VERSION ""

NS_ :

BS_:

BU_: IMU PBX DDU7 VCU

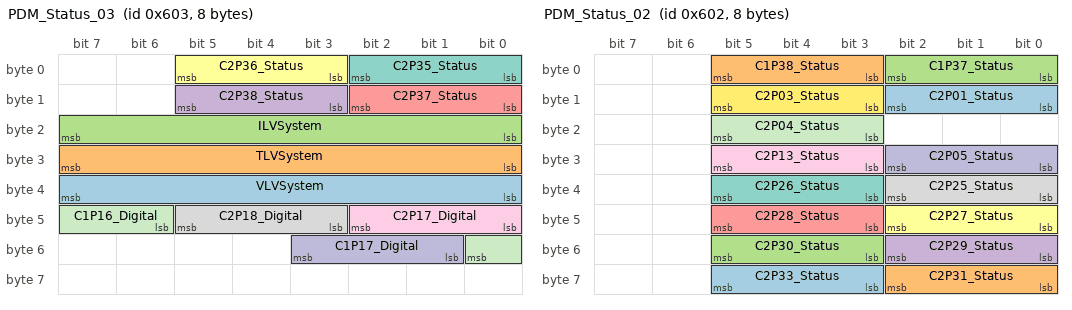
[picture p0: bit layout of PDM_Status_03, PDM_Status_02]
BO_ 1539 PDM_Status_03: 8 PBX
 SG_ VLVSystem : 32|8@1+ (0.1,0) [0|25.5] ""  VCU
 SG_ TLVSystem : 24|8@1+ (1,0) [0|255] ""  VCU
 SG_ ILVSystem : 16|8@1+ (1,0) [0|255] ""  VCU
 SG_ C2P38_Status : 11|3@1- (1,0) [0|0] ""  VCU
 SG_ C2P37_Status : 8|3@1- (1,0) [0|0] ""  VCU
 SG_ C2P36_Status : 3|3@1- (1,0) [0|0] ""  VCU
 SG_ C2P35_Status : 0|3@1- (1,0) [0|0] ""  VCU
 SG_ C2P18_Digital : 43|3@1- (1,0) [0|0] ""  VCU
 SG_ C2P17_Digital : 40|3@1- (1,0) [0|0] ""  VCU
 SG_ C1P17_Digital : 49|3@1- (1,0) [-4|3] ""  VCU
 SG_ C1P16_Digital : 46|3@1- (1,0) [0|0] ""  VCU

BO_ 1538 PDM_Status_02: 8 PBX
 SG_ C2P33_Status : 59|3@1- (1,0) [0|0] ""  VCU
 SG_ C2P31_Status : 56|3@1- (1,0) [0|0] ""  VCU
 SG_ C2P30_Status : 51|3@1- (1,0) [0|0] ""  VCU
 SG_ C2P29_Status : 48|3@1- (1,0) [0|0] ""  VCU
 SG_ C2P28_Status : 43|3@1- (1,0) [0|0] ""  VCU
 SG_ C2P27_Status : 40|3@1- (1,0) [0|0] ""  VCU
 SG_ C2P26_Status : 35|3@1- (1,0) [0|0] ""  VCU
 SG_ C2P25_Status : 32|3@1- (1,0) [0|0] ""  VCU
 SG_ C2P13_Status : 27|3@1- (1,0) [0|0] ""  VCU
 SG_ C2P05_Status : 24|3@1- (1,0) [0|0] ""  VCU
 SG_ C2P04_Status : 19|3@1- (1,0) [0|0] ""  VCU
 SG_ C2P03_Status : 11|3@1- (1,0) [0|0] ""  VCU
 SG_ C2P01_Status : 8|3@1- (1,0) [0|0] ""  VCU
 SG_ C1P38_Status : 3|3@1- (1,0) [0|0] ""  VCU
 SG_ C1P37_Status : 0|3@1- (1,0) [0|0] ""  VCU

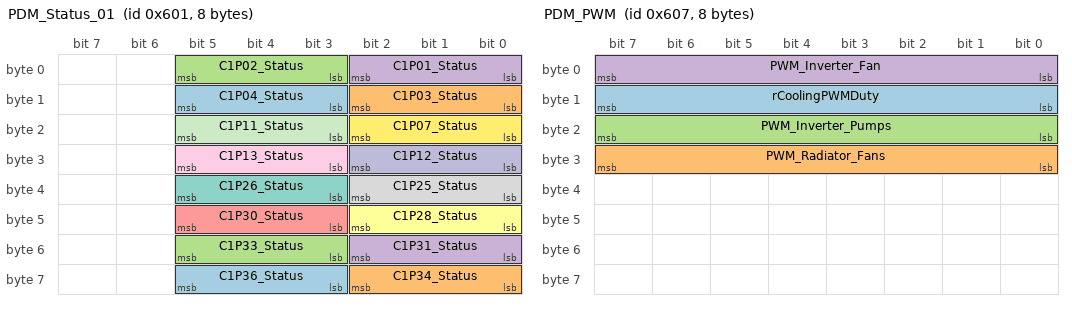
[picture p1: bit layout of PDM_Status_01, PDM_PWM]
BO_ 1537 PDM_Status_01: 8 PBX
 SG_ C1P36_Status : 59|3@1- (1,0) [0|0] ""  VCU
 SG_ C1P34_Status : 56|3@1- (1,0) [0|0] ""  VCU
 SG_ C1P33_Status : 51|3@1- (1,0) [0|0] ""  VCU
 SG_ C1P31_Status : 48|3@1- (1,0) [0|0] ""  VCU
 SG_ C1P30_Status : 43|3@1- (1,0) [0|0] ""  VCU
 SG_ C1P28_Status : 40|3@1- (1,0) [0|0] ""  VCU
 SG_ C1P26_Status : 35|3@1- (1,0) [0|0] ""  VCU
 SG_ C1P25_Status : 32|3@1- (1,0) [0|0] ""  VCU
 SG_ C1P13_Status : 27|3@1- (1,0) [0|0] ""  VCU
 SG_ C1P12_Status : 24|3@1- (1,0) [0|0] ""  VCU
 SG_ C1P11_Status : 19|3@1- (1,0) [0|0] ""  VCU
 SG_ C1P07_Status : 16|3@1- (1,0) [-4|3] ""  VCU
 SG_ C1P04_Status : 11|3@1- (1,0) [0|0] ""  VCU
 SG_ C1P03_Status : 8|3@1- (1,0) [0|0] ""  VCU
 SG_ C1P02_Status : 3|3@1- (1,0) [-4|3] ""  VCU
 SG_ C1P01_Status : 0|3@1- (1,0) [-4|3] ""  VCU

BO_ 1536 PDM_Req: 8 PBX
 SG_ C2P01 : 14|1@1+ (1,0) [0|0] ""  VCU
 SG_ C2P38 : 35|1@1+ (1,0) [0|0] ""  VCU
 SG_ C2P37 : 34|1@1+ (1,0) [0|0] ""  VCU
 SG_ C2P36 : 33|1@1+ (1,0) [0|1] ""  VCU
 SG_ C2P33 : 30|1@1+ (1,0) [0|1] ""  VCU
 SG_ C2P31 : 28|1@1+ (1,0) [0|1] ""  VCU
 SG_ C2P29 : 26|1@1+ (1,0) [0|1] ""  VCU
 SG_ C2P28 : 25|1@1+ (1,0) [0|0] ""  VCU
 SG_ C2P27 : 23|1@1+ (1,0) [0|0] ""  VCU
 SG_ C2P26 : 22|1@1+ (1,0) [0|0] ""  VCU
 SG_ C2P25 : 36|1@1+ (1,0) [0|1] ""  VCU
 SG_ C2P05 : 17|1@1+ (1,0) [0|0] ""  VCU
 SG_ C2P04 : 16|1@1+ (1,0) [0|1] ""  VCU
 SG_ C2P03 : 24|1@1+ (1,0) [0|0] ""  VCU
 SG_ C1P38 : 13|1@1+ (1,0) [0|0] ""  VCU
 SG_ C1P37 : 42|1@1+ (1,0) [0|1] ""  VCU
 SG_ C1P36 : 41|1@1+ (1,0) [0|1] ""  VCU
 SG_ C1P34 : 11|1@1+ (1,0) [0|1] ""  VCU
 SG_ C1P33 : 10|1@1+ (1,0) [0|1] ""  VCU
 SG_ C1P30 : 8|1@1+ (1,0) [0|1] ""  VCU
 SG_ C1P28 : 7|1@1+ (1,0) [0|1] ""  VCU
 SG_ C1P25 : 5|1@1+ (1,0) [0|1] ""  VCU
 SG_ C1P13 : 3|1@1+ (1,0) [0|1] ""  VCU
 SG_ C1P11_Hbridge : 39|2@1+ (1,0) [0|3] ""  VCU
 SG_ C1P07 : 38|1@1+ (1,0) [0|1] ""  VCU
 SG_ C1P04 : 2|1@1+ (1,0) [0|1] ""  VCU
 SG_ C1P03 : 1|1@1+ (1,0) [0|0] ""  VCU
 SG_ C1P02 : 0|1@1+ (1,0) [0|1] ""  VCU
 SG_ C1P01 : 37|1@1+ (1,0) [0|1] ""  VCU
 SG_ BReadyToDriveBuzzerRequest : 32|1@1+ (1,0) [0|1] ""  VCU
 SG_ BInvLVOnRequest : 9|1@1+ (1,0) [0|1] ""  VCU
 SG_ BBrakeLightOnRequest : 27|1@1+ (1,0) [0|1] ""  VCU
 SG_ BAccumulatorFanOnRequest : 15|1@1+ (1,0) [0|255] ""  VCU

BO_ 1543 PDM_PWM: 8 PBX
 SG_ rCoolingPWMDuty : 8|8@1+ (1,0) [0|255] ""  VCU
 SG_ PWM_Radiator_Fans : 24|8@1+ (1,0) [0|255] ""  VCU
 SG_ PWM_Inverter_Pumps : 16|8@1+ (1,0) [0|0] ""  VCU
 SG_ PWM_Inverter_Fan : 0|8@1+ (1,0) [0|0] ""  VCU

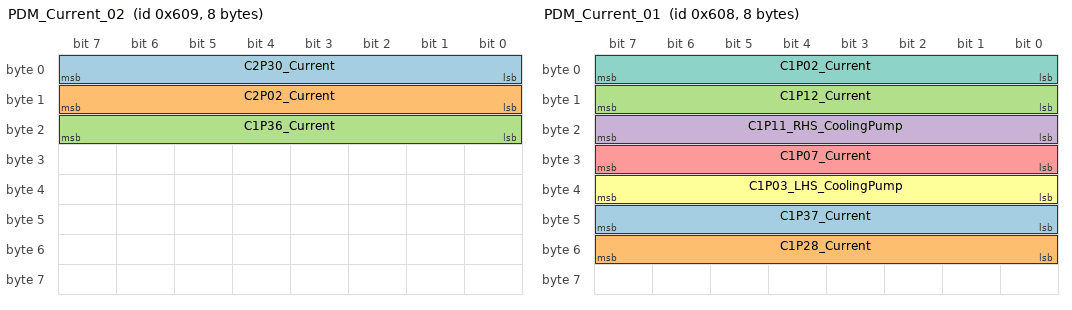
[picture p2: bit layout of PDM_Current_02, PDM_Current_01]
BO_ 1545 PDM_Current_02: 8 PBX
 SG_ C2P30_Current : 0|8@1- (1,0) [0|0] ""  VCU
 SG_ C2P02_Current : 8|8@1- (1,0) [-128|127] ""  VCU
 SG_ C1P36_Current : 16|8@1- (1,0) [0|0] ""  VCU

BO_ 1544 PDM_Current_01: 8 PBX
 SG_ C1P37_Current : 40|8@1- (1,0) [0|0] ""  VCU
 SG_ C1P28_Current : 48|8@1- (1,0) [-128|127] ""  VCU
 SG_ C1P12_Current : 8|8@1- (1,0) [-128|127] ""  VCU
 SG_ C1P11_RHS_CoolingPump : 16|8@1- (1,0) [0|0] ""  VCU
 SG_ C1P07_Current : 24|8@1- (1,0) [-128|127] ""  VCU
 SG_ C1P03_LHS_CoolingPump : 32|8@1- (1,0) [-128|127] ""  VCU
 SG_ C1P02_Current : 0|8@1- (1,0) [-128|127] ""  VCU

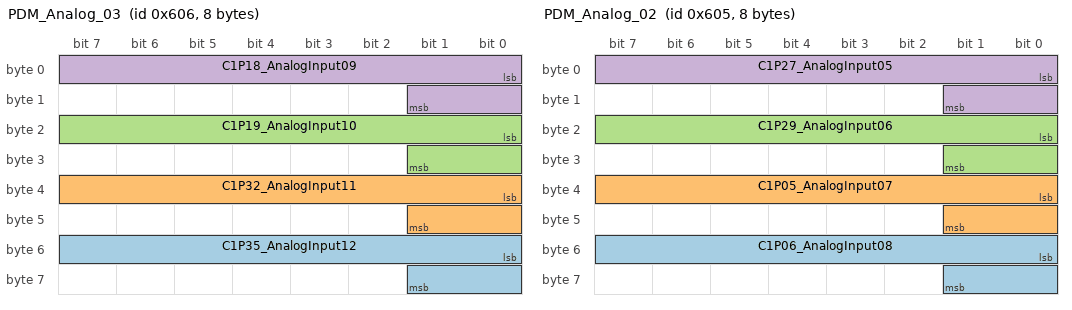
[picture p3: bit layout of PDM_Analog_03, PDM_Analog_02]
BO_ 1542 PDM_Analog_03: 8 PBX
 SG_ C1P35_AnalogInput12 : 48|10@1+ (0.005,0) [0|5.115] ""  VCU
 SG_ C1P32_AnalogInput11 : 32|10@1+ (0.005,0) [0|5.115] ""  VCU
 SG_ C1P19_AnalogInput10 : 16|10@1+ (0.005,0) [0|0] ""  VCU
 SG_ C1P18_AnalogInput09 : 0|10@1+ (0.005,0) [0|0] ""  VCU

BO_ 1541 PDM_Analog_02: 8 PBX
 SG_ C1P06_AnalogInput08 : 48|10@1+ (0.005,0) [0|5.115] ""  VCU
 SG_ C1P05_AnalogInput07 : 32|10@1+ (0.005,0) [0|5.115] ""  VCU
 SG_ C1P29_AnalogInput06 : 16|10@1+ (0.005,0) [0|5.115] ""  VCU
 SG_ C1P27_AnalogInput05 : 0|10@1+ (0.005,0) [0|5.115] ""  VCU

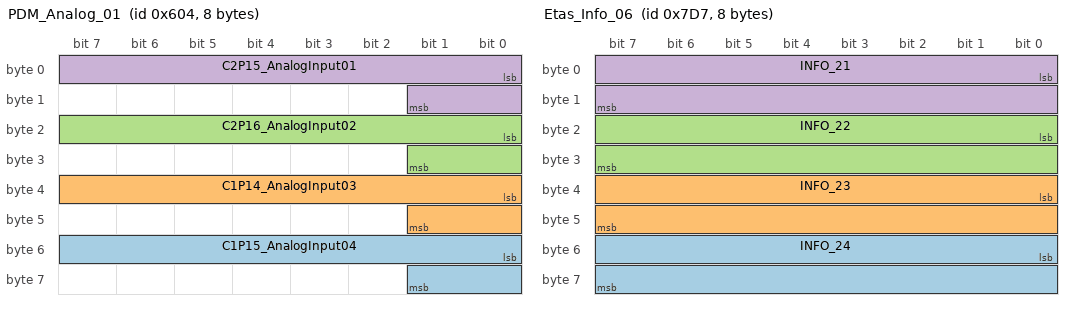
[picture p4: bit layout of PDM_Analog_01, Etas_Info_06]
BO_ 1540 PDM_Analog_01: 8 PBX
 SG_ C1P15_AnalogInput04 : 48|10@1+ (0.005,0) [0|5.115] ""  VCU
 SG_ C1P14_AnalogInput03 : 32|10@1+ (0.005,0) [0|5.115] ""  VCU
 SG_ C2P16_AnalogInput02 : 16|10@1+ (0.005,0) [0|5.115] ""  VCU
 SG_ C2P15_AnalogInput01 : 0|10@1+ (0.005,0) [0|5.115] ""  VCU

BO_ 2007 Etas_Info_06: 8 Vector__XXX
 SG_ INFO_24 : 48|16@1- (1,0) [0|0] "" Vector__XXX
 SG_ INFO_23 : 32|16@1- (1,0) [0|0] "" Vector__XXX
 SG_ INFO_22 : 16|16@1- (1,0) [0|0] "" Vector__XXX
 SG_ INFO_21 : 0|16@1- (1,0) [0|0] "" Vector__XXX

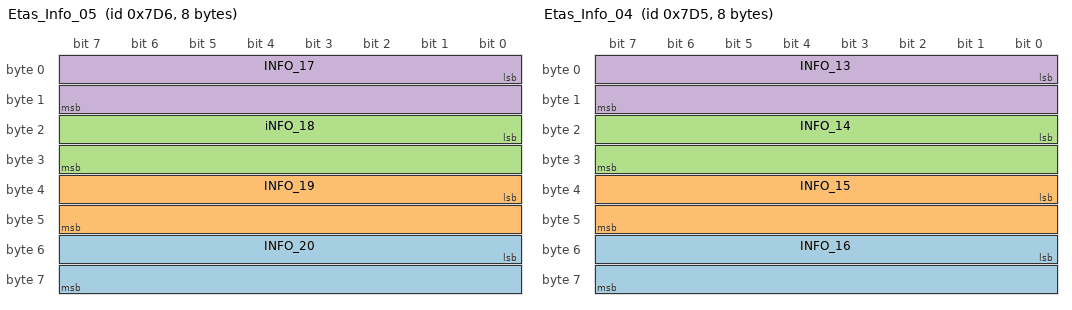
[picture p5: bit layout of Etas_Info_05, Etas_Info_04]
BO_ 2006 Etas_Info_05: 8 Vector__XXX
 SG_ INFO_20 : 48|16@1- (1,0) [0|0] "" Vector__XXX
 SG_ INFO_19 : 32|16@1- (1,0) [0|0] "" Vector__XXX
 SG_ iNFO_18 : 16|16@1- (1,0) [0|0] "" Vector__XXX
 SG_ INFO_17 : 0|16@1- (1,0) [0|0] "" Vector__XXX

BO_ 2005 Etas_Info_04: 8 Vector__XXX
 SG_ INFO_16 : 48|16@1- (1,0) [0|0] "" Vector__XXX
 SG_ INFO_15 : 32|16@1- (1,0) [0|0] "" Vector__XXX
 SG_ INFO_14 : 16|16@1- (1,0) [0|0] "" Vector__XXX
 SG_ INFO_13 : 0|16@1- (1,0) [0|0] "" Vector__XXX

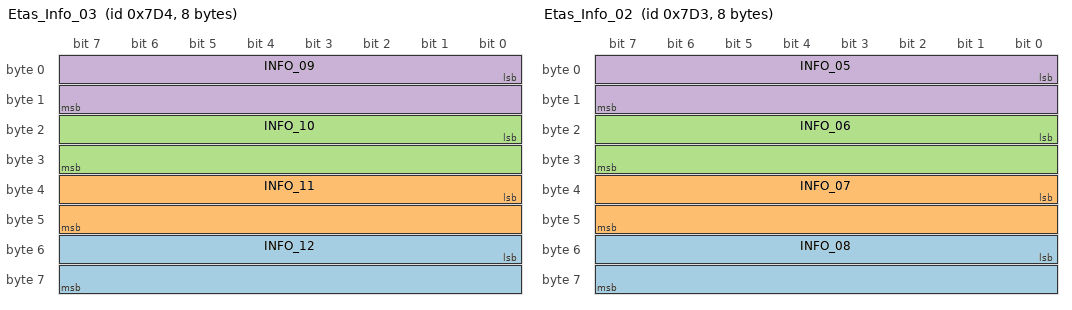
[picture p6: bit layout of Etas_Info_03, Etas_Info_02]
BO_ 2004 Etas_Info_03: 8 Vector__XXX
 SG_ INFO_12 : 48|16@1- (1,0) [0|0] "" Vector__XXX
 SG_ INFO_11 : 32|16@1- (1,0) [0|0] "" Vector__XXX
 SG_ INFO_10 : 16|16@1- (1,0) [0|0] "" Vector__XXX
 SG_ INFO_09 : 0|16@1- (1,0) [0|0] "" Vector__XXX

BO_ 2003 Etas_Info_02: 8 Vector__XXX
 SG_ INFO_08 : 48|16@1- (1,0) [0|0] "" Vector__XXX
 SG_ INFO_07 : 32|16@1- (1,0) [0|0] "" Vector__XXX
 SG_ INFO_06 : 16|16@1- (1,0) [0|0] "" Vector__XXX
 SG_ INFO_05 : 0|16@1- (1,0) [0|0] "" Vector__XXX

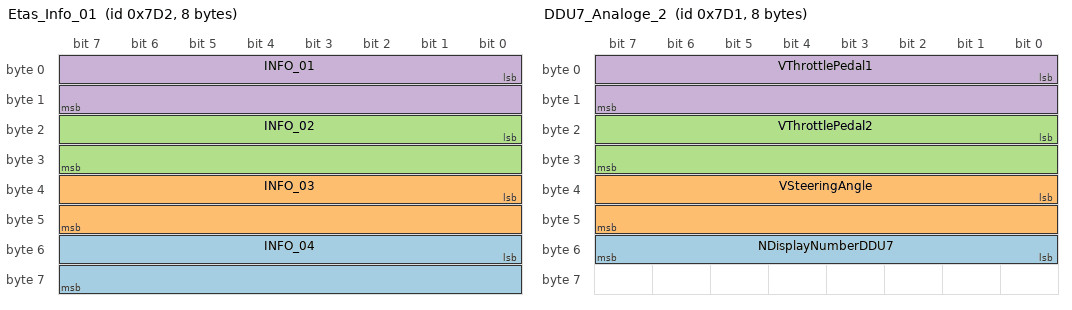
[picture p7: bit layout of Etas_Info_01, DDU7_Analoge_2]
BO_ 2002 Etas_Info_01: 8 Vector__XXX
 SG_ INFO_04 : 48|16@1- (1,0) [0|0] "" Vector__XXX
 SG_ INFO_03 : 32|16@1- (1,0) [-32768|32767] "" Vector__XXX
 SG_ INFO_02 : 16|16@1- (1,0) [-32768|32767] "" Vector__XXX
 SG_ INFO_01 : 0|16@1- (1,0) [-32768|32767] "" Vector__XXX

BO_ 2001 DDU7_Analoge_2: 8 DDU7
 SG_ NDisplayNumberDDU7 : 48|8@1+ (1,0) [0|255] ""  VCU
 SG_ VSteeringAngle : 32|16@1+ (0.1,0) [0|6553.5] ""  VCU
 SG_ VThrottlePedal2 : 16|16@1+ (0.1,0) [0|6553.5] ""  VCU
 SG_ VThrottlePedal1 : 0|16@1+ (0.1,0) [0|6553.5] ""  VCU

BO_ 2000 DDU7_Analoge_1: 8 DDU7
 SG_ pBrakeR : 16|16@1- (0.005,0) [-163.84|163.835] ""  VCU
 SG_ pBrakeF : 0|16@1- (0.005,0) [-163.84|163.835] ""  VCU

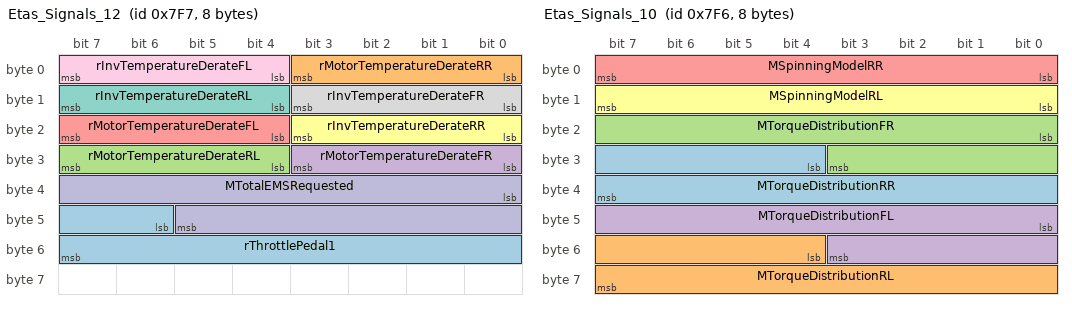
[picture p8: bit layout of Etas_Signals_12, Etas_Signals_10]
BO_ 2039 Etas_Signals_12: 8 VCU
 SG_ rThrottlePedal1 : 46|10@1+ (0.1,0) [0|102.3] "" Vector__XXX
 SG_ rMotorTemperatureDerateRR : 0|4@1+ (0.1,0) [0|1.5] "" Vector__XXX
 SG_ rMotorTemperatureDerateRL : 28|4@1+ (0.1,0) [0|0] "" Vector__XXX
 SG_ rMotorTemperatureDerateFR : 24|4@1+ (0.1,0) [0|1.5] "" Vector__XXX
 SG_ rMotorTemperatureDerateFL : 20|4@1+ (0.1,0) [0|1.5] "" Vector__XXX
 SG_ rInvTemperatureDerateRR : 16|4@1+ (0.1,0) [0|1.5] "" Vector__XXX
 SG_ rInvTemperatureDerateRL : 12|4@1+ (0.1,0) [0|1.5] "" Vector__XXX
 SG_ rInvTemperatureDerateFR : 8|4@1+ (0.1,0) [0|1.5] "" Vector__XXX
 SG_ rInvTemperatureDerateFL : 4|4@1+ (0.1,0) [0|1.5] "" Vector__XXX
 SG_ MTotalEMSRequested : 32|14@1- (0.1,300) [-519.2|1119.1] "" Vector__XXX

BO_ 2038 Etas_Signals_10: 8 VCU
 SG_ MTorqueDistributionRR : 28|12@1- (0.1,50) [-154.8|254.7] "" Vector__XXX
 SG_ MTorqueDistributionRL : 52|12@1- (0.1,50) [-154.8|254.7] "" Vector__XXX
 SG_ MTorqueDistributionFR : 16|12@1- (0.1,50) [-154.8|254.7] "" Vector__XXX
 SG_ MTorqueDistributionFL : 40|12@1- (0.1,50) [-154.8|254.7] "" Vector__XXX
 SG_ MSpinningModelRR : 0|8@1+ (0.1,0) [0|25.5] "" Vector__XXX
 SG_ MSpinningModelRL : 8|8@1+ (0.1,0) [0|0] "" Vector__XXX

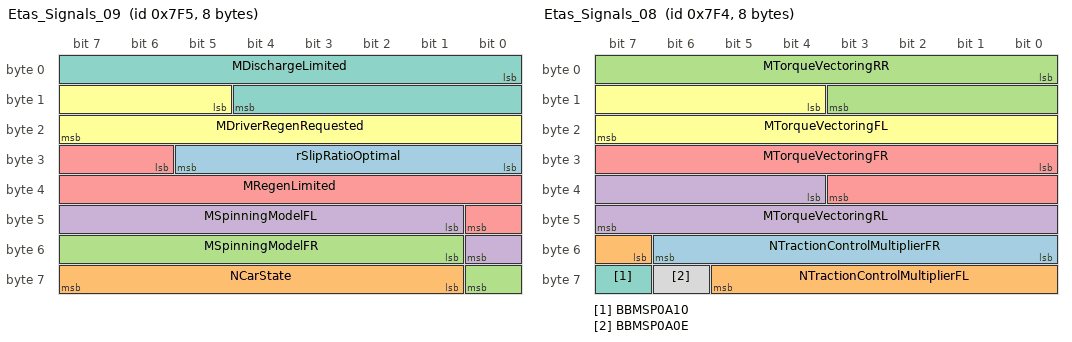
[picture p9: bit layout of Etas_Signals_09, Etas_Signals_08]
BO_ 2037 Etas_Signals_09: 8 VCU
 SG_ rSlipRatioOptimal : 24|6@1+ (0.01,0) [0|0.63] "" Vector__XXX
 SG_ NCarState : 57|7@1+ (1,0) [0|127] "" Vector__XXX
 SG_ MSpinningModelFR : 49|8@1+ (0.1,0) [0|0] "" Vector__XXX
 SG_ MSpinningModelFL : 41|8@1+ (0.1,0) [0|0] "" Vector__XXX
 SG_ MRegenLimited : 30|11@1+ (-0.1,0) [-204.7|0] "" Vector__XXX
 SG_ MDriverRegenRequested : 13|11@1+ (-0.1,0) [-204.7|0] "" Vector__XXX
 SG_ MDischargeLimited : 0|13@1+ (0.1,0) [0|819.1] "" Vector__XXX

BO_ 2036 Etas_Signals_08: 8 VCU
 SG_ NTractionControlMultiplierFR : 48|7@1+ (0.01,0) [0|1.27] "" Vector__XXX
 SG_ NTractionControlMultiplierFL : 55|7@1+ (0.01,0) [0|1.27] "" Vector__XXX
 SG_ MTorqueVectoringRR : 0|12@1- (0.1,50) [-154.8|254.7] "" Vector__XXX
 SG_ MTorqueVectoringRL : 36|12@1- (0.1,50) [-154.8|254.7] "" Vector__XXX
 SG_ MTorqueVectoringFR : 24|12@1- (0.1,50) [-154.8|254.7] "" Vector__XXX
 SG_ MTorqueVectoringFL : 12|12@1- (0.1,50) [-154.8|254.7] "" Vector__XXX
 SG_ BBMSP0A10 : 63|1@1+ (1,0) [0|1] "" Vector__XXX
 SG_ BBMSP0A0E : 62|1@1+ (1,0) [0|1] "" Vector__XXX

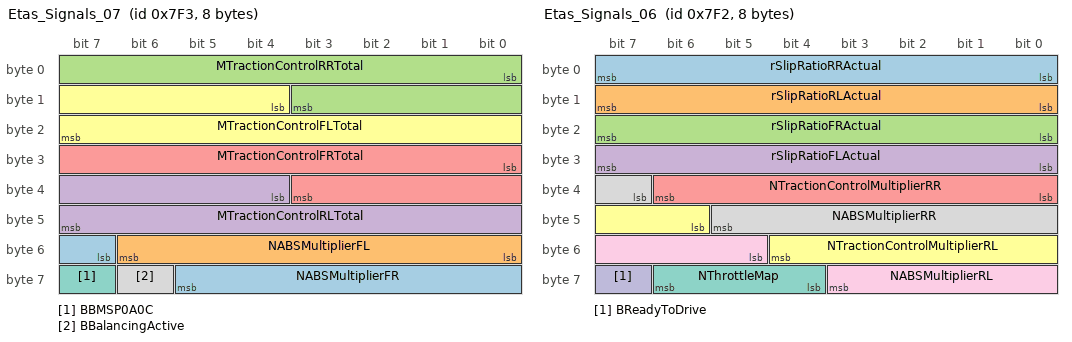
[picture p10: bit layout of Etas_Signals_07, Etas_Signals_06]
BO_ 2035 Etas_Signals_07: 8 VCU
 SG_ NABSMultiplierFR : 55|7@1+ (0.01,0) [0|1.27] "" Vector__XXX
 SG_ NABSMultiplierFL : 48|7@1+ (0.01,0) [0|1.27] "" Vector__XXX
 SG_ MTractionControlRRTotal : 0|12@1- (0.1,50) [-154.8|254.7] "" Vector__XXX
 SG_ MTractionControlRLTotal : 36|12@1- (0.1,50) [-154.8|254.7] "" Vector__XXX
 SG_ MTractionControlFRTotal : 24|12@1- (0.1,50) [-154.8|254.7] "" Vector__XXX
 SG_ MTractionControlFLTotal : 12|12@1- (0.1,50) [0|0] "" Vector__XXX
 SG_ BBMSP0A0C : 63|1@1+ (1,0) [0|1] "" Vector__XXX
 SG_ BBalancingActive : 62|1@1+ (1,0) [0|1] "" Vector__XXX

BO_ 2034 Etas_Signals_06: 8 VCU
 SG_ rSlipRatioRRActual : 0|8@1- (0.01,0) [-1.28|1.27] "" Vector__XXX
 SG_ rSlipRatioRLActual : 8|8@1- (0.01,0) [-1.28|1.27] "" Vector__XXX
 SG_ rSlipRatioFRActual : 16|8@1- (0.01,0) [-1.28|1.27] "" Vector__XXX
 SG_ rSlipRatioFLActual : 24|8@1- (0.01,0) [-1.28|1.27] "" Vector__XXX
 SG_ NTractionControlMultiplierRR : 32|7@1+ (0.01,0) [0|1.27] "" Vector__XXX
 SG_ NTractionControlMultiplierRL : 46|7@1+ (0.01,0) [0|1.27] "" Vector__XXX
 SG_ NThrottleMap : 60|3@1+ (1,0) [0|7] "" Vector__XXX
 SG_ NABSMultiplierRR : 39|7@1+ (0.01,0) [0|1.27] "" Vector__XXX
 SG_ NABSMultiplierRL : 53|7@1+ (0.01,0) [0|1.27] "" Vector__XXX
 SG_ BReadyToDrive : 63|1@1+ (1,0) [0|1] "" Vector__XXX

BO_ 2033 Etas_Signals_05: 8 VCU
 SG_ sChassis m1 : 0|15@1+ (1,0) [0|32767] "" Vector__XXX
 SG_ rTorqueVectoringMultiplier m1 : 21|7@1+ (0.01,0) [0|1.27] "" Vector__XXX
 SG_ rSOE m0 : 0|14@1+ (0.01,0) [0|163.83] "" Vector__XXX
 SG_ rSOC m0 : 14|14@1+ (0.01,0) [0|163.83] "" Vector__XXX
 SG_ PRegen m1 : 15|6@1+ (1,0) [0|63] "" Vector__XXX
 SG_ PEngineBraking m0 : 28|5@1+ (1,0) [0|31] "" Vector__XXX
 SG_ NPowerControllerKpSelector m0 : 33|3@1+ (1,0) [0|7] "" Vector__XXX
 SG_ NTorqueSplitSpeedSelector m0 : 36|1@1+ (1,1) [1|2] "" Vector__XXX
 SG_ NModeNumberDisplay6 m1 : 32|4@1+ (1,0) [0|15] "" Vector__XXX
 SG_ NModeNumberDisplay5 m1 : 28|4@1+ (1,0) [0|15] "" Vector__XXX
 SG_ NInvState m1 : 43|9@1+ (1,0) [0|511] "" Vector__XXX
 SG_ NBMSState m1 : 36|7@1+ (1,0) [0|127] "" Vector__XXX
 SG_ NBMSDLC m0 : 37|1@1+ (1,0) [0|1] "" Vector__XXX
 SG_ Multiplexer05 M : 63|1@1+ (1,0) [0|511] "" Vector__XXX

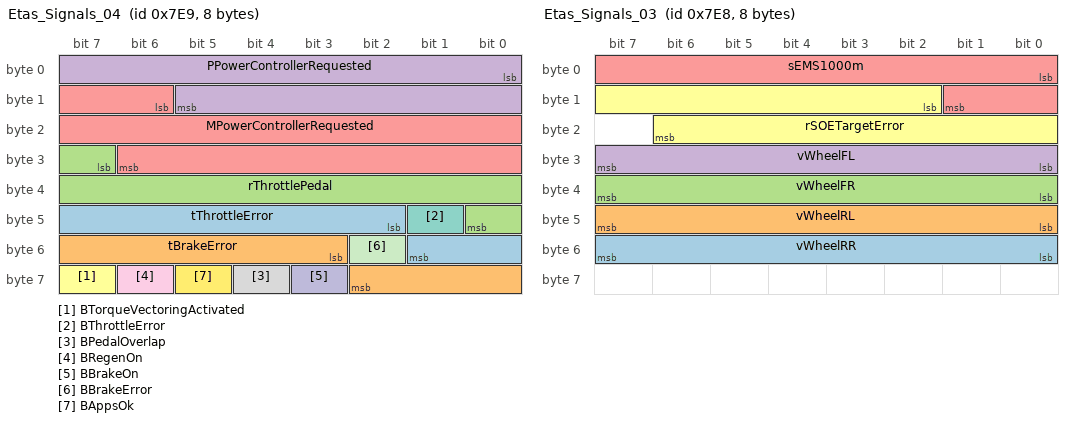
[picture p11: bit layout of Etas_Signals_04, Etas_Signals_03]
BO_ 2025 Etas_Signals_04: 8 VCU
 SG_ tThrottleError : 42|8@1+ (0.1,0) [0|25.5] "" Vector__XXX
 SG_ tBrakeError : 51|8@1+ (0.1,0) [0|25.5] "" Vector__XXX
 SG_ rThrottlePedal : 31|10@1+ (0.1,0) [0|102.3] "" Vector__XXX
 SG_ PPowerControllerRequested : 0|14@1- (0.01,30) [-51.92|111.91] "" Vector__XXX
 SG_ MPowerControllerRequested : 14|17@1- (0.01,300) [-355.36|955.35] "" Vector__XXX
 SG_ BTorqueVectoringActivated : 63|1@1+ (1,0) [0|1] "" Vector__XXX
 SG_ BThrottleError : 41|1@1+ (1,0) [0|1] "" Vector__XXX
 SG_ BPedalOverlap : 60|1@1+ (1,0) [0|1] "" Vector__XXX
 SG_ BRegenOn : 62|1@1+ (1,0) [0|1] "" Vector__XXX
 SG_ BBrakeOn : 59|1@1+ (1,0) [0|1] "" Vector__XXX
 SG_ BBrakeError : 50|1@1+ (1,0) [0|1] "" Vector__XXX
 SG_ BAppsOk : 61|1@1+ (1,0) [0|1] "" Vector__XXX

BO_ 2024 Etas_Signals_03: 8 VCU
 SG_ vWheelRR : 48|8@1+ (0.1,0) [0|25.5] "" Vector__XXX
 SG_ vWheelRL : 40|8@1+ (0.1,0) [0|25.5] "" Vector__XXX
 SG_ vWheelFR : 32|8@1+ (0.1,0) [0|25.5] "" Vector__XXX
 SG_ vWheelFL : 24|8@1+ (0.1,0) [0|25.5] "" Vector__XXX
 SG_ sEMS1000m : 0|10@1+ (1,0) [0|1023] "" Vector__XXX
 SG_ rSOETargetError : 10|13@1- (0.001,0) [-4.096|4.095] "" Vector__XXX

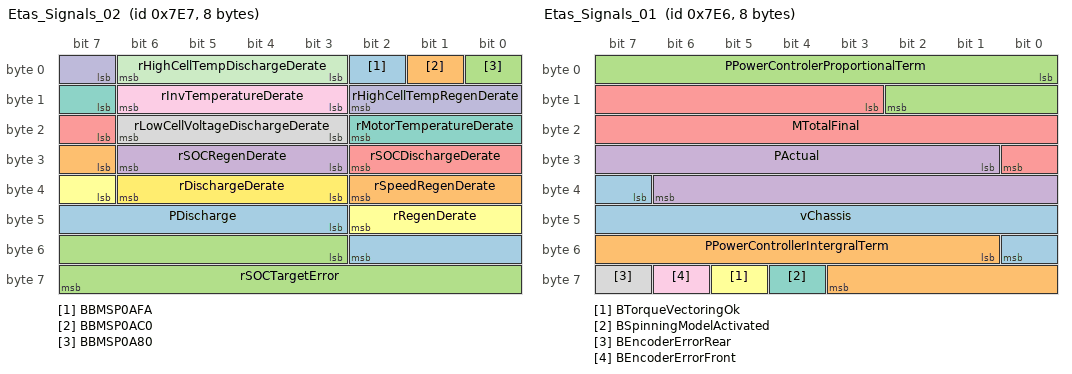
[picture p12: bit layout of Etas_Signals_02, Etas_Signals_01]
BO_ 2023 Etas_Signals_02: 8 VCU
 SG_ PDischarge : 43|8@1+ (1,0) [0|255] "" Vector__XXX
 SG_ rSpeedRegenDerate : 31|4@1+ (0.1,0) [0|1.5] "" Vector__XXX
 SG_ rSOCTargetError : 51|13@1- (0.001,0) [-4.096|4.095] "" Vector__XXX
 SG_ rSOCRegenDerate : 27|4@1+ (0.1,0) [0|1.5] "" Vector__XXX
 SG_ rSOCDischargeDerate : 23|4@1+ (0.1,0) [0|1.5] "" Vector__XXX
 SG_ rRegenDerate : 39|4@1+ (0.1,0) [0|1.5] "" Vector__XXX
 SG_ rMotorTemperatureDerate : 15|4@1+ (0.1,0) [0|1.5] "" Vector__XXX
 SG_ rLowCellVoltageDischargeDerate : 19|4@1+ (0.1,0) [0|1.5] "" Vector__XXX
 SG_ rInvTemperatureDerate : 11|4@1+ (0.1,0) [0|1.5] "" Vector__XXX
 SG_ rHighCellTempRegenDerate : 7|4@1+ (0.1,0) [0|1.5] "" Vector__XXX
 SG_ rHighCellTempDischargeDerate : 3|4@1+ (0.1,0) [0|1.5] "" Vector__XXX
 SG_ rDischargeDerate : 35|4@1+ (0.1,0) [0|1.5] "" Vector__XXX
 SG_ BBMSP0AFA : 2|1@1+ (1,0) [0|1] "" Vector__XXX
 SG_ BBMSP0AC0 : 1|1@1+ (1,0) [0|1] "" Vector__XXX
 SG_ BBMSP0A80 : 0|1@1+ (1,0) [0|1] "" Vector__XXX

BO_ 2022 Etas_Signals_01: 8 VCU
 SG_ vChassis : 39|10@1- (0.1,0) [-51.2|51.1] "" Vector__XXX
 SG_ PPowerControllerIntergralTerm : 49|11@1- (0.01,0) [-10.24|10.23] "" Vector__XXX
 SG_ PPowerControlerProportionalTerm : 0|11@1- (0.01,0) [-10.24|10.23] "" Vector__XXX
 SG_ PActual : 25|14@1- (0.01,30) [-51.92|111.91] "" Vector__XXX
 SG_ MTotalFinal : 11|14@1- (0.1,300) [0|0] "" Vector__XXX
 SG_ BTorqueVectoringOk : 61|1@1+ (1,0) [0|1] "" Vector__XXX
 SG_ BSpinningModelActivated : 60|1@1+ (1,0) [0|1] "" Vector__XXX
 SG_ BEncoderErrorRear : 63|1@1+ (1,0) [0|1] "" Vector__XXX
 SG_ BEncoderErrorFront : 62|1@1+ (1,0) [0|1] "" Vector__XXX

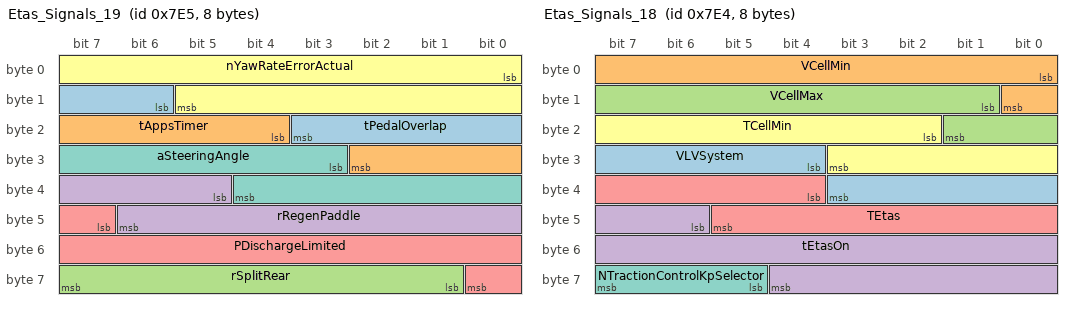
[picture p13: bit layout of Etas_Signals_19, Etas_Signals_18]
BO_ 2021 Etas_Signals_19: 8 VCU
 SG_ tPedalOverlap : 14|6@1+ (0.1,0) [0|6.3] "" Vector__XXX
 SG_ tAppsTimer : 20|7@1+ (0.01,0) [0|1.27] "" Vector__XXX
 SG_ rSplitRear : 57|7@1+ (0.01,0) [0|1.27] "" Vector__XXX
 SG_ rRegenPaddle : 37|10@1+ (0.1,0) [0|102.3] "" Vector__XXX
 SG_ PDischargeLimited : 47|10@1+ (0.1,0) [0|102.3] "" Vector__XXX
 SG_ nYawRateErrorActual : 0|14@1- (0.01,0) [-81.92|81.91] "" Vector__XXX
 SG_ aSteeringAngle : 27|10@1- (0.1,0) [-51.2|51.1] "" Vector__XXX

BO_ 2020 Etas_Signals_18: 8 VCU
 SG_ VLVSystem : 28|8@1+ (0.1,0) [0|25.5] "" Vector__XXX
 SG_ VCellMin : 0|9@1+ (0.01,0) [0|5.11] "" Vector__XXX
 SG_ VCellMax : 9|9@1+ (0.01,0) [0|5.11] "" Vector__XXX
 SG_ tEtasOn : 46|15@1+ (0.1,0) [0|3276.7] "" Vector__XXX
 SG_ TEtas : 36|10@1+ (0.1,0) [0|102.3] "" Vector__XXX
 SG_ TCellMin : 18|10@1+ (0.1,0) [0|102.3] "" Vector__XXX
 SG_ NTractionControlKpSelector : 61|3@1+ (1,0) [0|7] "" Vector__XXX

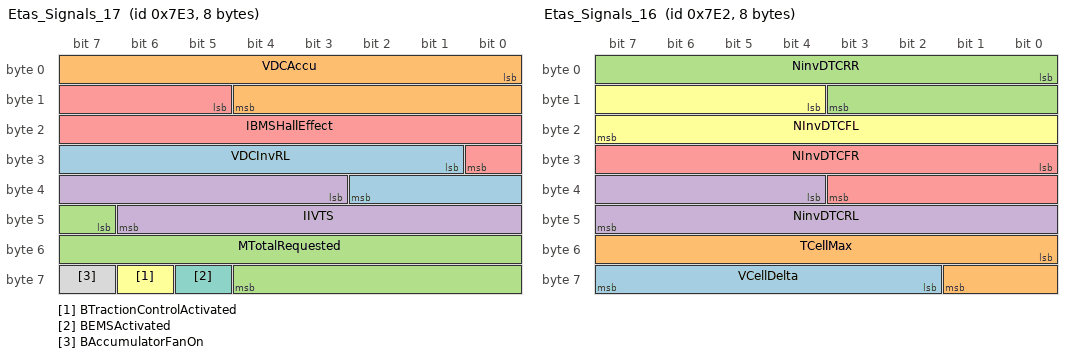
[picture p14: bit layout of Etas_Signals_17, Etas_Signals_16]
BO_ 2019 Etas_Signals_17: 8 VCU
 SG_ VDCInvRL : 25|10@1+ (1,0) [0|1023] "" Vector__XXX
 SG_ VDCAccu : 0|13@1+ (0.1,0) [0|819.1] "" Vector__XXX
 SG_ MTotalRequested : 47|14@1- (0.1,300) [-519.2|1119.1] "" Vector__XXX
 SG_ IIVTS : 35|12@1- (0.1,20) [-184.8|224.7] "" Vector__XXX
 SG_ IBMSHallEffect : 13|12@1- (0.1,20) [-184.8|224.7] "" Vector__XXX
 SG_ BTractionControlActivated : 62|1@1+ (1,0) [0|1] "" Vector__XXX
 SG_ BEMSActivated : 61|1@1+ (1,0) [0|1] "" Vector__XXX
 SG_ BAccumulatorFanOn : 63|1@1+ (1,0) [0|1] "" Vector__XXX

BO_ 2018 Etas_Signals_16: 8 VCU
 SG_ VCellDelta : 58|6@1+ (0.01,0) [0|0.63] "" Vector__XXX
 SG_ TCellMax : 48|10@1+ (0.1,0) [0|102.3] "" Vector__XXX
 SG_ NinvDTCRR : 0|12@1+ (1,0) [0|4095] "" Vector__XXX
 SG_ NinvDTCRL : 36|12@1+ (1,0) [0|4095] "" Vector__XXX
 SG_ NInvDTCFR : 24|12@1+ (1,0) [0|4095] "" Vector__XXX
 SG_ NInvDTCFL : 12|12@1+ (1,0) [0|4095] "" Vector__XXX

BO_ 2017 Etas_Signals_15: 8 VCU
 SG_ TMotorRR m0 : 34|11@1+ (0.1,0) [0|204.7] "" Vector__XXX
 SG_ TMotorRL m0 : 23|11@1+ (0.1,0) [0|204.7] "" Vector__XXX
 SG_ TMotorMax m0 : 45|11@1+ (0.1,0) [0|204.7] "" Vector__XXX
 SG_ TMotorFR m0 : 0|11@1+ (0.1,0) [0|204.7] "" Vector__XXX
 SG_ TMotorFL m0 : 12|11@1+ (0.1,0) [0|204.7] "" Vector__XXX
 SG_ TInvRR m1 : 0|10@1+ (0.1,0) [0|102.3] "" Vector__XXX
 SG_ TInvRL m1 : 40|10@1+ (0.1,0) [0|102.3] "" Vector__XXX
 SG_ TInvMax m1 : 30|10@1+ (0.1,0) [0|102.3] "" Vector__XXX
 SG_ TInvFR m1 : 20|10@1+ (0.1,0) [0|102.3] "" Vector__XXX
 SG_ TInvFL m1 : 10|10@1+ (0.1,0) [0|102.3] "" Vector__XXX
 SG_ Multiplexer15 M : 62|2@1+ (1,0) [0|3] "" Vector__XXX

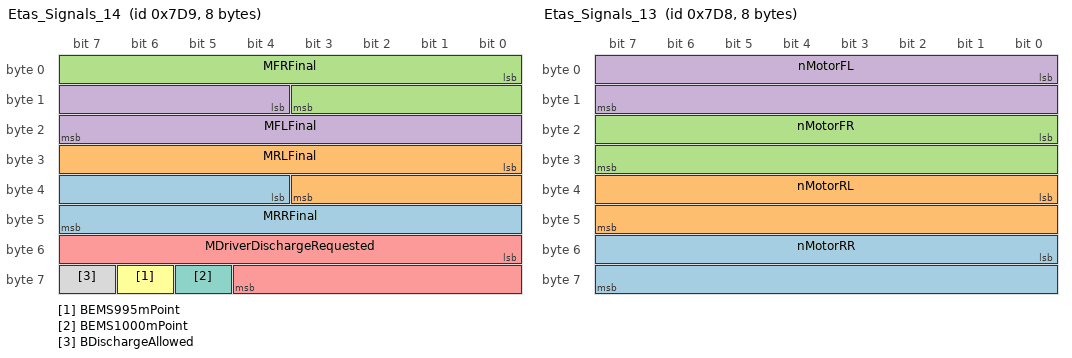
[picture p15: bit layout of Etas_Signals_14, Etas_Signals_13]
BO_ 2009 Etas_Signals_14: 8 VCU
 SG_ MRRFinal : 36|12@1- (0.1,50) [-154.8|254.7] "" Vector__XXX
 SG_ MRLFinal : 24|12@1- (0.1,50) [-154.8|254.7] "" Vector__XXX
 SG_ MFRFinal : 0|12@1- (0.1,50) [-154.8|254.7] "" Vector__XXX
 SG_ MFLFinal : 12|12@1- (0.1,50) [-154.8|254.7] "" Vector__XXX
 SG_ MDriverDischargeRequested : 48|13@1+ (0.1,0) [0|819.1] "" Vector__XXX
 SG_ BEMS995mPoint : 62|1@1+ (1,0) [0|1] "" Vector__XXX
 SG_ BEMS1000mPoint : 61|1@1+ (1,0) [0|1] "" Vector__XXX
 SG_ BDischargeAllowed : 63|1@1+ (1,0) [0|1] "" Vector__XXX

BO_ 2008 Etas_Signals_13: 8 VCU
 SG_ nMotorRR : 48|16@1- (1,0) [-32768|32767] "" Vector__XXX
 SG_ nMotorRL : 32|16@1- (1,0) [-32768|32767] "" Vector__XXX
 SG_ nMotorFR : 16|16@1- (1,0) [-32768|32767] "" Vector__XXX
 SG_ nMotorFL : 0|16@1- (1,0) [-32768|32767] "rpm" Vector__XXX

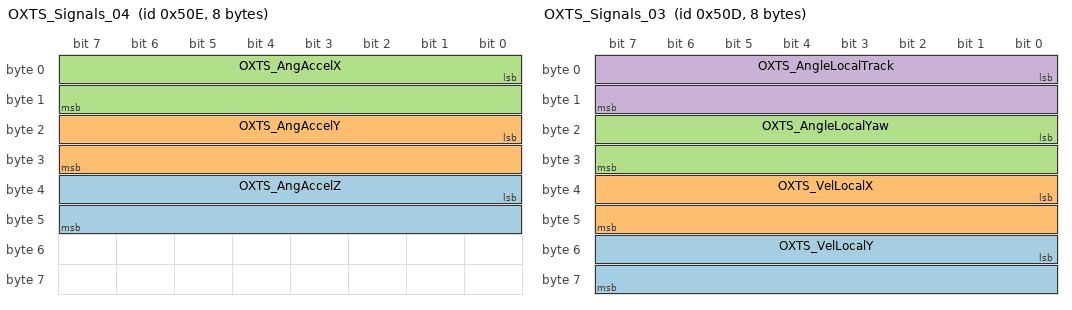
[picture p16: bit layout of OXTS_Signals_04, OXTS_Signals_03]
BO_ 1294 OXTS_Signals_04: 8 IMU
 SG_ OXTS_AngAccelZ : 32|16@1- (0.01,0) [-327.68|327.67] ""  VCU
 SG_ OXTS_AngAccelY : 16|16@1- (0.01,0) [-327.68|327.67] ""  VCU
 SG_ OXTS_AngAccelX : 0|16@1- (0.01,0) [-327.68|327.67] ""  VCU

BO_ 1293 OXTS_Signals_03: 8 IMU
 SG_ OXTS_VelLocalY : 48|16@1- (0.01,0) [-327.68|327.67] ""  VCU
 SG_ OXTS_VelLocalX : 32|16@1- (0.01,0) [-327.68|327.67] ""  VCU
 SG_ OXTS_AngleLocalYaw : 16|16@1- (0.01,0) [-327.68|327.67] ""  VCU
 SG_ OXTS_AngleLocalTrack : 0|16@1- (0.01,0) [-327.68|327.67] ""  VCU

BO_ 1292 OXTS_Signals_02: 8 IMU
 SG_ OXTS_PosLocalY : 32|32@1- (0.0001,0) [-214748.3648|214748.3647] ""  VCU
 SG_ OXTS_PosLocalX : 0|32@1- (0.001,0) [-2147483.648|2147483.647] ""  VCU

BO_ 1291 OXTS_Signals_12: 8 IMU
 SG_ OXTS_DistanceWithHold : 32|32@1+ (0.001,0) [0|4294967.295] ""  VCU
 SG_ OXTS_Distance : 0|32@1+ (0.001,0) [0|4294967.295] ""  VCU

BO_ 1290 OXTS_Signals_11: 8 IMU
 SG_ OXTS_AngleSlip : 0|16@1- (0.01,0) [-327.68|327.67] ""  VCU

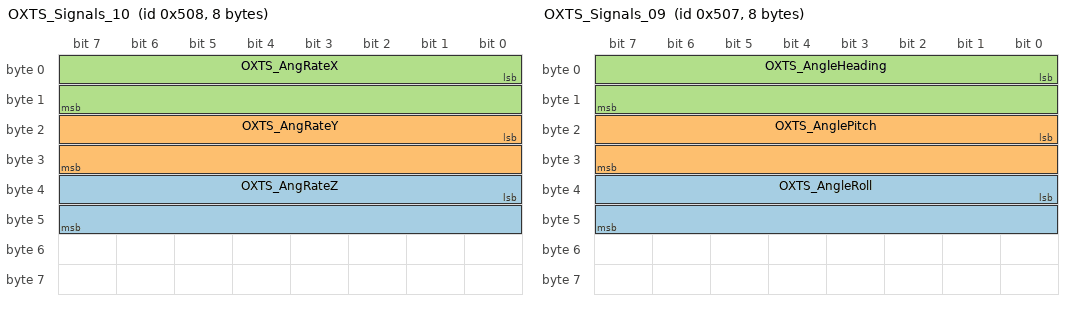
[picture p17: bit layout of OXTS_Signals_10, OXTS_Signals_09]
BO_ 1288 OXTS_Signals_10: 8 IMU
 SG_ OXTS_AngRateZ : 32|16@1- (0.01,0) [-327.68|327.67] ""  VCU
 SG_ OXTS_AngRateY : 16|16@1- (0.01,0) [-327.68|327.67] ""  VCU
 SG_ OXTS_AngRateX : 0|16@1- (0.01,0) [-327.68|327.67] ""  VCU

BO_ 1287 OXTS_Signals_09: 8 IMU
 SG_ OXTS_AngleRoll : 32|16@1+ (0.01,0) [0|655.35] ""  VCU
 SG_ OXTS_AnglePitch : 16|16@1- (0.01,0) [-327.68|327.67] ""  VCU
 SG_ OXTS_AngleHeading : 0|16@1+ (0.01,0) [0|655.35] ""  VCU

BO_ 1286 OXTS_Signals_08: 8 IMU
 SG_ OXTS_AccelSlip : 0|16@1- (0.01,0) [-327.68|327.67] ""  VCU

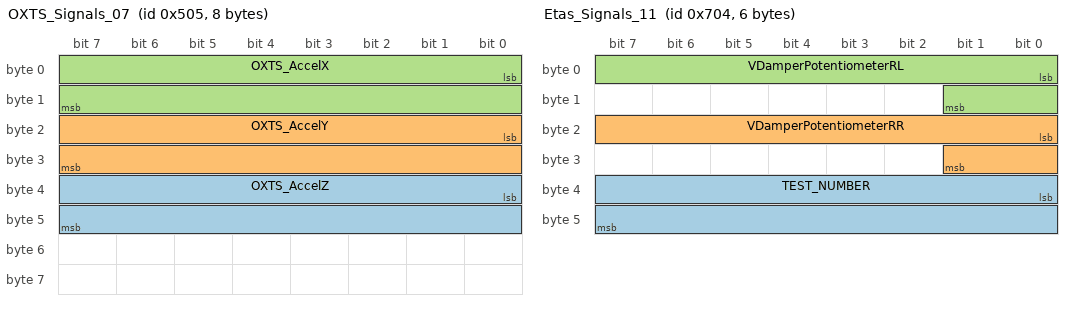
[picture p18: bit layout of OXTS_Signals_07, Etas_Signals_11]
BO_ 1285 OXTS_Signals_07: 8 IMU
 SG_ OXTS_AccelZ : 32|16@1- (0.01,0) [-327.68|327.67] ""  VCU
 SG_ OXTS_AccelY : 16|16@1- (0.01,0) [-327.68|327.67] ""  VCU
 SG_ OXTS_AccelX : 0|16@1- (0.01,0) [-327.68|327.67] ""  VCU

BO_ 1284 OXTS_Signals_06: 8 IMU
 SG_ OXTS_VelLateral : 16|16@1- (0.01,0) [-327.68|327.67] ""  VCU
 SG_ OXTS_VelForward : 0|16@1- (0.01,0) [-327.68|327.67] ""  VCU

BO_ 1283 OXTS_Signals_05: 8 IMU
 SG_ OXTS_Speed2D : 0|16@1- (0.01,0) [-327.68|327.67] ""  VCU

BO_ 1321 OXTS_Signals_01: 8 IMU
 SG_ OXTS_PosLon : 32|32@1- (1E-07,0) [-214.7483648|214.7483647] ""  VCU
 SG_ OXTS_PosLat : 0|32@1- (1E-07,0) [-214.7483648|214.7483647] ""  VCU

BO_ 1796 Etas_Signals_11: 6 VCU
 SG_ TEST_NUMBER : 32|16@1+ (1,0) [-32768|32767] "" Vector__XXX
 SG_ VDamperPotentiometerRR : 16|10@1+ (0.005,0) [0|5.115] "" Vector__XXX
 SG_ VDamperPotentiometerRL : 0|10@1+ (0.005,0) [0|5.115] "" Vector__XXX

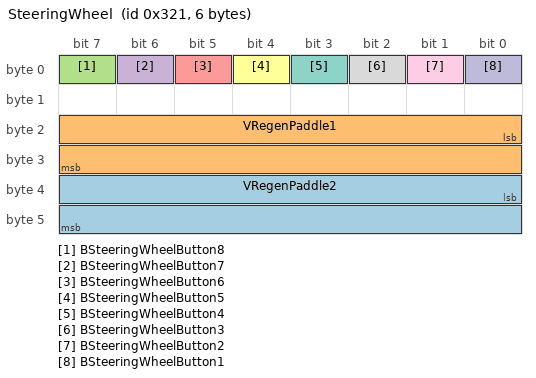
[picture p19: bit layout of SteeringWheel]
BO_ 801 SteeringWheel: 6 Vector__XXX
 SG_ VRegenPaddle2 : 32|16@1+ (0.001,0) [0|65.535] ""  VCU
 SG_ VRegenPaddle1 : 16|16@1+ (0.001,0) [0|65.535] ""  VCU
 SG_ BSteeringWheelButton8 : 7|1@1+ (1,0) [0|1] ""  VCU
 SG_ BSteeringWheelButton7 : 6|1@1+ (1,0) [0|1] ""  VCU
 SG_ BSteeringWheelButton6 : 5|1@1+ (1,0) [0|1] ""  VCU
 SG_ BSteeringWheelButton5 : 4|1@1+ (1,0) [0|1] ""  VCU
 SG_ BSteeringWheelButton4 : 3|1@1+ (1,0) [0|1] ""  VCU
 SG_ BSteeringWheelButton3 : 2|1@1+ (1,0) [0|1] ""  VCU
 SG_ BSteeringWheelButton2 : 1|1@1+ (1,0) [0|1] ""  VCU
 SG_ BSteeringWheelButton1 : 0|1@1+ (1,0) [0|1] ""  VCU

BO_TX_BU_ 1536 : VCU,PBX;

BA_DEF_ BO_  "VFrameFormat" ENUM  "vector_leerstring","Standard";
BA_DEF_ BO_  "GenMsgCycleTime" INT 0 5000;
BA_DEF_  "BusType" STRING ;
BA_DEF_DEF_  "VFrameFormat" "Standard";
BA_DEF_DEF_  "GenMsgCycleTime" 0;
BA_DEF_DEF_  "BusType" "CAN";
BA_ "GenMsgCycleTime" BO_ 1539 100;
BA_ "VFrameFormat" BO_ 1538 0;
BA_ "GenMsgCycleTime" BO_ 1538 100;
BA_ "GenMsgCycleTime" BO_ 1537 100;
BA_ "GenMsgCycleTime" BO_ 1536 100;
BA_ "VFrameFormat" BO_ 1543 0;
BA_ "GenMsgCycleTime" BO_ 1543 100;
BA_ "GenMsgCycleTime" BO_ 1545 100;
BA_ "GenMsgCycleTime" BO_ 1544 100;
BA_ "GenMsgCycleTime" BO_ 1542 100;
BA_ "VFrameFormat" BO_ 1542 0;
BA_ "VFrameFormat" BO_ 1541 0;
BA_ "GenMsgCycleTime" BO_ 1541 100;
BA_ "VFrameFormat" BO_ 1540 0;
BA_ "GenMsgCycleTime" BO_ 1540 100;
BA_ "GenMsgCycleTime" BO_ 2007 100;
BA_ "GenMsgCycleTime" BO_ 2006 100;
BA_ "GenMsgCycleTime" BO_ 2005 100;
BA_ "GenMsgCycleTime" BO_ 2004 100;
BA_ "GenMsgCycleTime" BO_ 2003 100;
BA_ "GenMsgCycleTime" BO_ 2002 100;
BA_ "GenMsgCycleTime" BO_ 2001 5;
BA_ "GenMsgCycleTime" BO_ 2000 5;
BA_ "GenMsgCycleTime" BO_ 2039 5;
BA_ "GenMsgCycleTime" BO_ 2038 20;
BA_ "GenMsgCycleTime" BO_ 2037 20;
BA_ "GenMsgCycleTime" BO_ 2036 20;
BA_ "GenMsgCycleTime" BO_ 2035 10;
BA_ "GenMsgCycleTime" BO_ 2034 10;
BA_ "GenMsgCycleTime" BO_ 2033 100;
BA_ "GenMsgCycleTime" BO_ 2025 10;
BA_ "GenMsgCycleTime" BO_ 2024 100;
BA_ "GenMsgCycleTime" BO_ 2023 100;
BA_ "GenMsgCycleTime" BO_ 2022 5;
BA_ "GenMsgCycleTime" BO_ 2021 10;
BA_ "GenMsgCycleTime" BO_ 2020 20;
BA_ "GenMsgCycleTime" BO_ 2019 10;
BA_ "GenMsgCycleTime" BO_ 2018 5;
BA_ "GenMsgCycleTime" BO_ 2017 100;
BA_ "VFrameFormat" BO_ 2017 0;
BA_ "GenMsgCycleTime" BO_ 2009 5;
BA_ "GenMsgCycleTime" BO_ 2008 10;
BA_ "VFrameFormat" BO_ 1294 0;
BA_ "GenMsgCycleTime" BO_ 1294 20;
BA_ "VFrameFormat" BO_ 1293 0;
BA_ "GenMsgCycleTime" BO_ 1293 20;
BA_ "VFrameFormat" BO_ 1292 0;
BA_ "GenMsgCycleTime" BO_ 1292 20;
BA_ "VFrameFormat" BO_ 1291 0;
BA_ "GenMsgCycleTime" BO_ 1291 20;
BA_ "VFrameFormat" BO_ 1290 0;
BA_ "GenMsgCycleTime" BO_ 1290 20;
BA_ "VFrameFormat" BO_ 1288 0;
BA_ "GenMsgCycleTime" BO_ 1288 20;
BA_ "VFrameFormat" BO_ 1287 0;
BA_ "GenMsgCycleTime" BO_ 1287 20;
BA_ "VFrameFormat" BO_ 1286 0;
BA_ "GenMsgCycleTime" BO_ 1286 20;
BA_ "VFrameFormat" BO_ 1285 0;
BA_ "GenMsgCycleTime" BO_ 1285 20;
BA_ "VFrameFormat" BO_ 1284 0;
BA_ "GenMsgCycleTime" BO_ 1284 20;
BA_ "VFrameFormat" BO_ 1283 0;
BA_ "GenMsgCycleTime" BO_ 1283 20;
BA_ "VFrameFormat" BO_ 1321 0;
BA_ "GenMsgCycleTime" BO_ 1321 20;
BA_ "VFrameFormat" BO_ 1796 0;
BA_ "GenMsgCycleTime" BO_ 1796 100;
BA_ "VFrameFormat" BO_ 801 0;
BA_ "GenMsgCycleTime" BO_ 801 100;
